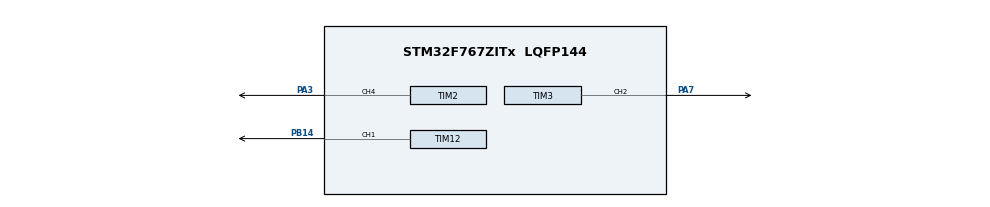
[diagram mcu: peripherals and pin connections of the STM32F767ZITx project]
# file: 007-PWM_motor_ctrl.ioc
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Mcu.Family=STM32F7
Mcu.Name=STM32F767ZITx
Mcu.Package=LQFP144
NVIC.PriorityGroup=NVIC_PRIORITYGROUP_4
PA3.Signal=S_TIM2_CH4
PA7.Signal=S_TIM3_CH2
PB14.Signal=S_TIM12_CH1
ProjectManager.HeapSize=0x200
ProjectManager.StackSize=0x400
ProjectManager.TargetToolchain=STM32CubeIDE
RCC.HSE_VALUE=25000000
RCC.HSI_VALUE=16000000
RCC.LSE_VALUE=32768
RCC.USBFreq_Value=96000000
RCC.VCOOutputFreq_Value=192000000
SH.S_TIM12_CH1.0=TIM12_CH1,PWM Generation1 CH1
SH.S_TIM2_CH4.0=TIM2_CH4,PWM Generation4 CH4
SH.S_TIM3_CH2.0=TIM3_CH2,PWM Generation2 CH2
TIM12.Channel-PWM\ Generation1\ CH1=TIM_CHANNEL_1
TIM12.Period=62500
TIM12.Prescaler=128
TIM12.Pulse-PWM\ Generation1\ CH1=31250
TIM2.Channel-PWM\ Generation4\ CH4=TIM_CHANNEL_4
TIM2.Period=1023
TIM2.Pulse-PWM\ Generation4\ CH4=102
TIM3.Channel-PWM\ Generation2\ CH2=TIM_CHANNEL_2
TIM3.Period=1023
TIM3.Prescaler=128
TIM3.Pulse-PWM\ Generation2\ CH2=102
VP_TIM12_VS_ClockSourceINT.Mode=Internal
VP_TIM2_VS_ClockSourceINT.Mode=Internal
VP_TIM3_VS_ClockSourceINT.Mode=Internal
board=custom

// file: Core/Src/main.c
/* USER CODE BEGIN Header */
/**
  ******************************************************************************
  * @file           : main.c
  * @brief          : Main program body
  ******************************************************************************
  * @attention
  *
  * Copyright (c) 2022 STMicroelectronics.
  * All rights reserved.
  *
  * This software is licensed under terms that can be found in the LICENSE file
  * in the root directory of this software component.
  * If no LICENSE file comes with this software, it is provided AS-IS.
  *
  ******************************************************************************
  */
/* USER CODE END Header */
#include "main.h"

TIM_HandleTypeDef htim2;
TIM_HandleTypeDef htim3;
TIM_HandleTypeDef htim12;

void SystemClock_Config(void);
static void MX_GPIO_Init(void);
static void MX_TIM2_Init(void);
static void MX_TIM3_Init(void);
static void MX_TIM12_Init(void);

int main(void)
{

  /* MCU Configuration--------------------------------------------------------*/

  /* Reset of all peripherals, Initializes the Flash interface and the Systick. */
  HAL_Init();

  /* Configure the system clock */
  SystemClock_Config();

  /* Initialize all configured peripherals */
  MX_GPIO_Init();
  MX_TIM2_Init();
  MX_TIM3_Init();
  MX_TIM12_Init();
  /* USER CODE BEGIN 2 */
  HAL_TIM_PWM_Start(&htim3,  TIM_CHANNEL_2); // PWM 488Hz
  HAL_TIM_PWM_Start(&htim2,  TIM_CHANNEL_4); // PWM 15kHz
  HAL_TIM_PWM_Start(&htim12, TIM_CHANNEL_1); // control LED
  /* USER CODE END 2 */

  /* Infinite loop */
  while (1)
  {

  }
}

void SystemClock_Config(void)
{
  RCC_OscInitTypeDef RCC_OscInitStruct = {0};
  RCC_ClkInitTypeDef RCC_ClkInitStruct = {0};

  /** Configure the main internal regulator output voltage
  */
  __HAL_RCC_PWR_CLK_ENABLE();
  __HAL_PWR_VOLTAGESCALING_CONFIG(PWR_REGULATOR_VOLTAGE_SCALE3);

  /** Initializes the RCC Oscillators according to the specified parameters
  * in the RCC_OscInitTypeDef structure.
  */
  RCC_OscInitStruct.OscillatorType = RCC_OSCILLATORTYPE_HSI;
  RCC_OscInitStruct.HSIState = RCC_HSI_ON;
  RCC_OscInitStruct.HSICalibrationValue = RCC_HSICALIBRATION_DEFAULT;
  RCC_OscInitStruct.PLL.PLLState = RCC_PLL_NONE;
  if (HAL_RCC_OscConfig(&RCC_OscInitStruct) != HAL_OK)
  {
    Error_Handler();
  }

  /** Initializes the CPU, AHB and APB buses clocks
  */
  RCC_ClkInitStruct.ClockType = RCC_CLOCKTYPE_HCLK|RCC_CLOCKTYPE_SYSCLK
                              |RCC_CLOCKTYPE_PCLK1|RCC_CLOCKTYPE_PCLK2;
  RCC_ClkInitStruct.SYSCLKSource = RCC_SYSCLKSOURCE_HSI;
  RCC_ClkInitStruct.AHBCLKDivider = RCC_SYSCLK_DIV1;
  RCC_ClkInitStruct.APB1CLKDivider = RCC_HCLK_DIV1;
  RCC_ClkInitStruct.APB2CLKDivider = RCC_HCLK_DIV1;

  if (HAL_RCC_ClockConfig(&RCC_ClkInitStruct, FLASH_LATENCY_0) != HAL_OK)
  {
    Error_Handler();
  }
}

static void MX_TIM2_Init(void)
{

  TIM_ClockConfigTypeDef sClockSourceConfig = {0};
  TIM_MasterConfigTypeDef sMasterConfig = {0};
  TIM_OC_InitTypeDef sConfigOC = {0};

  htim2.Instance = TIM2;
  htim2.Init.Prescaler = 0;
  htim2.Init.CounterMode = TIM_COUNTERMODE_UP;
  htim2.Init.Period = 1023;
  htim2.Init.ClockDivision = TIM_CLOCKDIVISION_DIV1;
  htim2.Init.AutoReloadPreload = TIM_AUTORELOAD_PRELOAD_DISABLE;
  if (HAL_TIM_Base_Init(&htim2) != HAL_OK)
  {
    Error_Handler();
  }
  sClockSourceConfig.ClockSource = TIM_CLOCKSOURCE_INTERNAL;
  if (HAL_TIM_ConfigClockSource(&htim2, &sClockSourceConfig) != HAL_OK)
  {
    Error_Handler();
  }
  if (HAL_TIM_PWM_Init(&htim2) != HAL_OK)
  {
    Error_Handler();
  }
  sMasterConfig.MasterOutputTrigger = TIM_TRGO_RESET;
  sMasterConfig.MasterSlaveMode = TIM_MASTERSLAVEMODE_DISABLE;
  if (HAL_TIMEx_MasterConfigSynchronization(&htim2, &sMasterConfig) != HAL_OK)
  {
    Error_Handler();
  }
  sConfigOC.OCMode = TIM_OCMODE_PWM1;
  sConfigOC.Pulse = 102;
  sConfigOC.OCPolarity = TIM_OCPOLARITY_HIGH;
  sConfigOC.OCFastMode = TIM_OCFAST_DISABLE;
  if (HAL_TIM_PWM_ConfigChannel(&htim2, &sConfigOC, TIM_CHANNEL_4) != HAL_OK)
  {
    Error_Handler();
  }
  HAL_TIM_MspPostInit(&htim2);

}

static void MX_TIM3_Init(void)
{

  TIM_ClockConfigTypeDef sClockSourceConfig = {0};
  TIM_MasterConfigTypeDef sMasterConfig = {0};
  TIM_OC_InitTypeDef sConfigOC = {0};

  htim3.Instance = TIM3;
  htim3.Init.Prescaler = 128;
  htim3.Init.CounterMode = TIM_COUNTERMODE_UP;
  htim3.Init.Period = 1023;
  htim3.Init.ClockDivision = TIM_CLOCKDIVISION_DIV1;
  htim3.Init.AutoReloadPreload = TIM_AUTORELOAD_PRELOAD_DISABLE;
  if (HAL_TIM_Base_Init(&htim3) != HAL_OK)
  {
    Error_Handler();
  }
  sClockSourceConfig.ClockSource = TIM_CLOCKSOURCE_INTERNAL;
  if (HAL_TIM_ConfigClockSource(&htim3, &sClockSourceConfig) != HAL_OK)
  {
    Error_Handler();
  }
  if (HAL_TIM_PWM_Init(&htim3) != HAL_OK)
  {
    Error_Handler();
  }
  sMasterConfig.MasterOutputTrigger = TIM_TRGO_RESET;
  sMasterConfig.MasterSlaveMode = TIM_MASTERSLAVEMODE_DISABLE;
  if (HAL_TIMEx_MasterConfigSynchronization(&htim3, &sMasterConfig) != HAL_OK)
  {
    Error_Handler();
  }
  sConfigOC.OCMode = TIM_OCMODE_PWM1;
  sConfigOC.Pulse = 102;
  sConfigOC.OCPolarity = TIM_OCPOLARITY_HIGH;
  sConfigOC.OCFastMode = TIM_OCFAST_DISABLE;
  if (HAL_TIM_PWM_ConfigChannel(&htim3, &sConfigOC, TIM_CHANNEL_2) != HAL_OK)
  {
    Error_Handler();
  }
  HAL_TIM_MspPostInit(&htim3);

}

static void MX_TIM12_Init(void)
{

  TIM_ClockConfigTypeDef sClockSourceConfig = {0};
  TIM_OC_InitTypeDef sConfigOC = {0};

  htim12.Instance = TIM12;
  htim12.Init.Prescaler = 128;
  htim12.Init.CounterMode = TIM_COUNTERMODE_UP;
  htim12.Init.Period = 62500;
  htim12.Init.ClockDivision = TIM_CLOCKDIVISION_DIV1;
  htim12.Init.AutoReloadPreload = TIM_AUTORELOAD_PRELOAD_DISABLE;
  if (HAL_TIM_Base_Init(&htim12) != HAL_OK)
  {
    Error_Handler();
  }
  sClockSourceConfig.ClockSource = TIM_CLOCKSOURCE_INTERNAL;
  if (HAL_TIM_ConfigClockSource(&htim12, &sClockSourceConfig) != HAL_OK)
  {
    Error_Handler();
  }
  if (HAL_TIM_PWM_Init(&htim12) != HAL_OK)
  {
    Error_Handler();
  }
  sConfigOC.OCMode = TIM_OCMODE_PWM1;
  sConfigOC.Pulse = 31250;
  sConfigOC.OCPolarity = TIM_OCPOLARITY_HIGH;
  sConfigOC.OCFastMode = TIM_OCFAST_DISABLE;
  if (HAL_TIM_PWM_ConfigChannel(&htim12, &sConfigOC, TIM_CHANNEL_1) != HAL_OK)
  {
    Error_Handler();
  }
  HAL_TIM_MspPostInit(&htim12);

}

static void MX_GPIO_Init(void)
{

  /* GPIO Ports Clock Enable */
  __HAL_RCC_GPIOA_CLK_ENABLE();
  __HAL_RCC_GPIOB_CLK_ENABLE();

}

void Error_Handler(void)
{
  __disable_irq();
  while (1)
  {
  }
}
